AUTOSAR XML (schema 4-0-3)
package /ComponentTypes
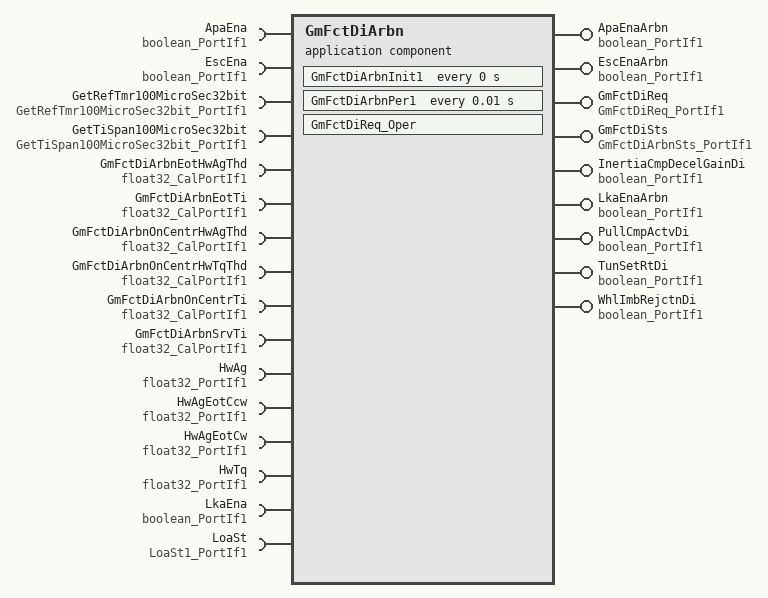
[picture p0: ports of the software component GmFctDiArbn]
  application sw component type GmFctDiArbn
    9 x provide port:
      ApaEnaArbn: nonqueued-sender-com-spec{data-element=Logl, init-value=0}, provided-interface=boolean_PortIf1
      EscEnaArbn: nonqueued-sender-com-spec{data-element=Logl, init-value=0}, provided-interface=boolean_PortIf1
      GmFctDiReq: server-com-spec{operation=Oper, queue-length=1}, provided-interface=GmFctDiReq_PortIf1
      GmFctDiSts: nonqueued-sender-com-spec{data-element=Val, init-value=0}, provided-interface=GmFctDiArbnSts_PortIf1
      InertiaCmpDecelGainDi: nonqueued-sender-com-spec{data-element=Logl, init-value=0}, provided-interface=boolean_PortIf1
      LkaEnaArbn: nonqueued-sender-com-spec{data-element=Logl, init-value=0}, provided-interface=boolean_PortIf1
      PullCmpActvDi: nonqueued-sender-com-spec{data-element=Logl, init-value=0}, provided-interface=boolean_PortIf1
      TunSetRtDi: nonqueued-sender-com-spec{data-element=Logl, init-value=0}, provided-interface=boolean_PortIf1
      WhlImbRejctnDi: nonqueued-sender-com-spec{data-element=Logl, init-value=0}, provided-interface=boolean_PortIf1
    16 x require port:
      ApaEna: nonqueued-receiver-com-spec{data-element=Logl, filter=data-filter-type=ALWAYS, init-value=0}, required-interface=boolean_PortIf1
      EscEna: nonqueued-receiver-com-spec{data-element=Logl, filter=data-filter-type=ALWAYS, init-value=0}, required-interface=boolean_PortIf1
      GetRefTmr100MicroSec32bit: required-interface=GetRefTmr100MicroSec32bit_PortIf1
      GetTiSpan100MicroSec32bit: required-interface=GetTiSpan100MicroSec32bit_PortIf1
      GmFctDiArbnEotHwAgThd: parameter-require-com-spec{init-value=20, parameter=Val}, required-interface=float32_CalPortIf1
      GmFctDiArbnEotTi: parameter-require-com-spec{init-value=1, parameter=Val}, required-interface=float32_CalPortIf1
      GmFctDiArbnOnCentrHwAgThd: parameter-require-com-spec{init-value=5, parameter=Val}, required-interface=float32_CalPortIf1
      GmFctDiArbnOnCentrHwTqThd: parameter-require-com-spec{init-value=0, parameter=Val}, required-interface=float32_CalPortIf1
      GmFctDiArbnOnCentrTi: parameter-require-com-spec{init-value=1, parameter=Val}, required-interface=float32_CalPortIf1
      GmFctDiArbnSrvTi: parameter-require-com-spec{init-value=15, parameter=Val}, required-interface=float32_CalPortIf1
      HwAg: nonqueued-receiver-com-spec{data-element=Val, filter=data-filter-type=ALWAYS, init-value=0}, required-interface=float32_PortIf1
      HwAgEotCcw: nonqueued-receiver-com-spec{data-element=Val, filter=data-filter-type=ALWAYS, init-value=-360}, required-interface=float32_PortIf1
      HwAgEotCw: nonqueued-receiver-com-spec{data-element=Val, filter=data-filter-type=ALWAYS, init-value=360}, required-interface=float32_PortIf1
      HwTq: nonqueued-receiver-com-spec{data-element=Val, filter=data-filter-type=ALWAYS, init-value=0}, required-interface=float32_PortIf1
      LkaEna: nonqueued-receiver-com-spec{data-element=Logl, filter=data-filter-type=ALWAYS, init-value=0}, required-interface=boolean_PortIf1
      LoaSt: nonqueued-receiver-com-spec{data-element=Val, filter=data-filter-type=ALWAYS, init-value=0}, required-interface=LoaSt1_PortIf1
    behavior GmFctDiArbn_InternalBehavior
      ar-typed-per-instance-memorys:
        9 x data, all with sw-calibration-access=READ-ONLY:
          CcwEotEnad: type=boolean
          CwEotEnad: type=boolean
          FctDiLtch: type=boolean
          InCcwEotRng: type=boolean
          InCcwEotRngElpdTi: type=uint32
          InCwEotRng: type=boolean
          InCwEotRngElpdTi: type=uint32
          InOnCentrRng: type=boolean
          OnCentrElpdTi: type=uint32
      timing event GmFctDiArbn_InitEvent: start-on-event=GmFctDiArbnInit1, period=0
      timing event TMT_GmFctDiArbnPer1: start-on-event=GmFctDiArbnPer1, period=0.01
      operation invoked event OIT_GmFctDiReq_Oper_GmFctDiReq_Oper: start-on-event=GmFctDiReq_Oper, operation=GmFctDiReq.Oper
      explicit-inter-runnable-variables:
        data FctDiReq: type=boolean, init-value=0
        data FctDiStrtTi: type=uint32, init-value=0
      runnable GmFctDiArbnInit1
      runnable GmFctDiArbnPer1
        data-receive-point-by-arguments:
          8 x access:
            REC_ApaEna_Logl: accessed-variable=ApaEna.Logl
            REC_EscEna_Logl: accessed-variable=EscEna.Logl
            REC_HwAg_Val: accessed-variable=HwAg.Val
            REC_HwAgEotCcw_Val: accessed-variable=HwAgEotCcw.Val
            REC_HwAgEotCw_Val: accessed-variable=HwAgEotCw.Val
            REC_HwTq_Val: accessed-variable=HwTq.Val
            REC_LkaEna_Logl: accessed-variable=LkaEna.Logl
            REC_LoaSt_Val: accessed-variable=LoaSt.Val
        data-send-points:
          8 x access:
            SEND_ApaEnaArbn_Logl: accessed-variable=ApaEnaArbn.Logl
            SEND_EscEnaArbn_Logl: accessed-variable=EscEnaArbn.Logl
            SEND_GmFctDiSts_Val: accessed-variable=GmFctDiSts.Val
            SEND_InertiaCmpDecelGainDi_Logl: accessed-variable=InertiaCmpDecelGainDi.Logl
            SEND_LkaEnaArbn_Logl: accessed-variable=LkaEnaArbn.Logl
            SEND_PullCmpActvDi_Logl: accessed-variable=PullCmpActvDi.Logl
            SEND_TunSetRtDi_Logl: accessed-variable=TunSetRtDi.Logl
            SEND_WhlImbRejctnDi_Logl: accessed-variable=WhlImbRejctnDi.Logl
        read-local-variables:
          access READ_FctDiReq: accessed-variable=FctDiReq
          access READ_FctDiStrtTi: accessed-variable=FctDiStrtTi
        sync call SC_GetRefTmr100MicroSec32bit_Oper: operation=GetRefTmr100MicroSec32bit.Oper, timeout=0
        sync call SC_GetTiSpan100MicroSec32bit_Oper: operation=GetTiSpan100MicroSec32bit.Oper, timeout=0
      runnable GmFctDiReq_Oper
        sync call SC_GetRefTmr100MicroSec32bit_Oper: operation=GetRefTmr100MicroSec32bit.Oper, timeout=0
        written-local-variables:
          access WRITE_FctDiReq: accessed-variable=FctDiReq
          access WRITE_FctDiStrtTi: accessed-variable=FctDiStrtTi
  swc implementation GmFctDiArbn_Implementation: behavior=GmFctDiArbn_InternalBehavior
    code-descriptors:
      code Default: artifact-descriptors=autosar-engineering-object={short-label=Default, category=SWSRC}
